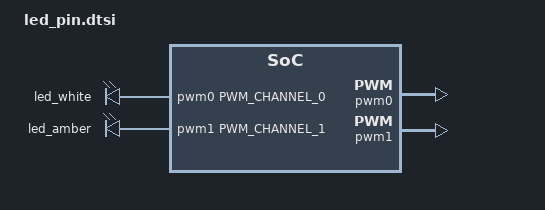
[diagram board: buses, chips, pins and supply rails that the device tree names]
/* Copyright 2026 The ChromiumOS Authors
 * Use of this source code is governed by a BSD-style license that can be
 * found in the LICENSE file.
 */

/ {
	pwm-leds {
		compatible = "pwm-leds";
		/* NOTE: &pwm number needs same with channel number */
		led_white: led-white {
			pwms = <&pwm0 PWM_CHANNEL_0 PWM_HZ(324) PWM_POLARITY_INVERTED>;
		};
		led_amber: led-amber {
			pwms = <&pwm1 PWM_CHANNEL_1 PWM_HZ(324) PWM_POLARITY_INVERTED>;
		};
	};

	led_pins: pwm-led-pins {
		compatible = "cros-ec,pwm-led-pins";

		combo_led: combo-led {
			led-id = "EC_LED_ID_BATTERY_LED";
			led-pwms = <&led_white &led_amber>;
			battery_led_off: color-off {
				led-color = "LED_OFF";
				led-values = <0 0>;
			};

			battery_led_white: color-white {
				led-color = "LED_WHITE";
				led-values = <100 0>;
			};

			battery_led_amber: color-amber {
				led-color = "LED_AMBER";
				led-values = <0 100 >;
			};
		};
	};
};

&pwm0 {
        status = "okay";
        pinctrl-0 = <&pwm0_gpc3>;
        clock-bus = "NPCX_CLOCK_BUS_LFCLK";
        pinctrl-names = "default";
};
&pwm1 {
        status = "okay";
        pinctrl-0 = <&pwm1_gpc2>;
	clock-bus = "NPCX_CLOCK_BUS_LFCLK";
        pinctrl-names = "default";
};

